# ADuCM363 register map
Vendor: Analog Devices Inc.; Series: ADuCM36x; File version: 0.1
CPU: CM3 r2p1, little endian, no MPU, no FPU, 3 interrupt priority bits
Registers are 16-bit, read-write, no defined reset value unless marked. A register's access mark holds for its fields unless they carry their own. Offsets are from the block's base; [hi:lo] are bit positions; {n}, {i} and the like mark numbered series.

## ADI_GPIO1 — General Purpose Input Output
Base 0x40006030
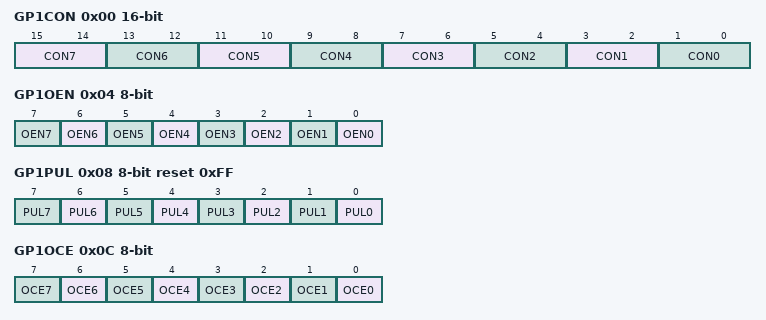
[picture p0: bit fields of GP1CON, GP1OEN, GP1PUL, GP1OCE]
0x00 GP1CON — GPIO Port 1 configuration
  [15:14] CON7 — Configuration bits for P1.7
    0=GPIOIRQ7; 1=PWM5; 2=SPI0CS
  [13:12] CON6 — Configuration bits for P1.6
    0=GPIOIRQ6; 1=PWM4; 2=SPI0MOSI
  [11:10] CON5 — Configuration bits for P1.5
    0=GPIOIRQ5; 1=PWM3; 2=SPI0SCLK
  [9:8] CON4 — Configuration bits for P1.4
    0=GPIO; 1=PWM2; 2=SPI0MISO
  [7:6] CON3 — Configuration bits for P1.3
    0=GPIO; 1=PWM1
  [5:4] CON2 — Configuration bits for P1.2
    0=GPIO; 1=PWM0
  [3:2] CON1 — Configuration bits for P1.1
    0=GPIOIRQ4; 1=PWMTRIP
  [1:0] CON0 — Configuration bits for P1.0
    0=GPIOIRQ3; 1=PWMSYNC; 2=EXTCLKIN
0x04 GP1OEN 8-bit — GPIO Port 1 output enable
  [all] fields
    0=IN; 1=OUT
  [n] OEN{n} (n=0..7) — Direction for port pin
0x08 GP1PUL 8-bit reset 0xFF (reset mask 0x0) — GPIO Port 1 output pull up enable.
  [all] fields
    0=DIS; 1=EN
  [n] PUL{n} (n=0..7) — Pull Up Enable for port pin
0x0C GP1OCE 8-bit — GPIO Port 1 tri state
  [all] fields
    0=DIS; 1=EN
  [n] OCE{n} (n=0..7) — open circuit Enable for port pin
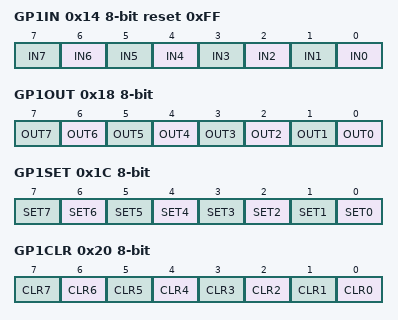
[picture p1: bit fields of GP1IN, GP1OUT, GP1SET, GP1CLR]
0x14 GP1IN 8-bit ro reset 0xFF (reset mask 0x0) — GPIO Port 1 data input.
  [all] fields
    0=LOW; 1=HIGH
  [n] IN{n} (n=0..7) — Input for port pin
0x18 GP1OUT 8-bit — GPIO Port 1 data out.
  [all] fields
    0=LOW; 1=HIGH
  [n] OUT{n} (n=0..7) — Output for port pin
0x1C GP1SET 8-bit wo — GPIO Port 1 data out set
  [all] fields
    1=SET
  [n] SET{n} (n=0..7) — Set Output High for port pin
0x20 GP1CLR 8-bit wo — GPIO Port 1 data out clear.
  [all] fields
    1=CLR
  [n] CLR{n} (n=0..7) — Set Output Low for port pin
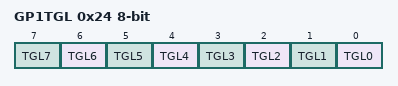
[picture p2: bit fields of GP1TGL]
0x24 GP1TGL 8-bit wo — GPIO Port 1 pin toggle.
  [all] fields
    1=TGL
  [n] TGL{n} (n=0..7) — Toggle Output for port pin

## ADI_GPIO2 — General Purpose Input Output
Base 0x40006060
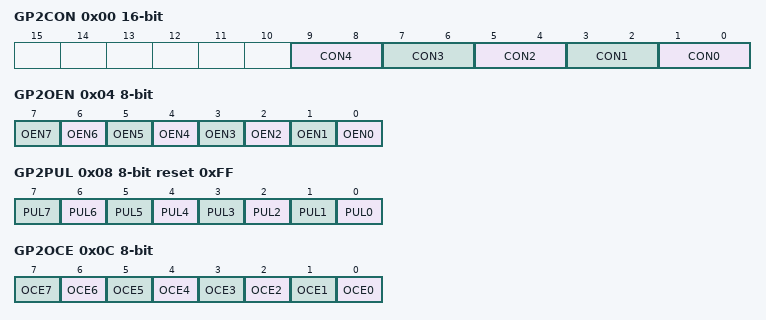
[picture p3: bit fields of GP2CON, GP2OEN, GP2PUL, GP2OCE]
0x00 GP2CON — GPIO Port 2 configuration
  [9:8] CON4 — Configuration bits for P2.4
    1=SWDATA
  [7:6] CON3 — Configuration bits for P2.3
    1=SWCLK
  [5:4] CON2 — Configuration bits for P2.2
    0=GPIO
  [3:2] CON1 — Configuration bits for P2.1
    0=GPIO; 1=I2CSDA
  [1:0] CON0 — Configuration bits for P2.0
    0=GPIO; 1=I2CSCL
0x04 GP2OEN 8-bit — GPIO Port 2 output enable
  [all] fields
    0=IN; 1=OUT
  [n] OEN{n} (n=0..7) — Direction for port pin
0x08 GP2PUL 8-bit reset 0xFF (reset mask 0x0) — GPIO Port 2 output pull up enable.
  [all] fields
    0=DIS; 1=EN
  [n] PUL{n} (n=0..7) — Pull Up Enable for port pin
0x0C GP2OCE 8-bit — GPIO Port 2 tri state
  [all] fields
    0=DIS; 1=EN
  [n] OCE{n} (n=0..7) — open circuit Enable for port pin
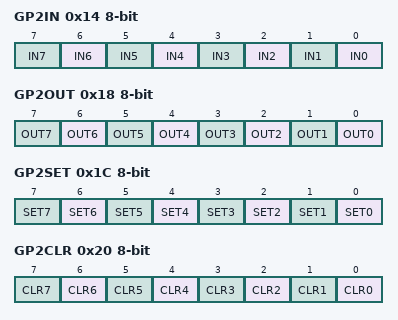
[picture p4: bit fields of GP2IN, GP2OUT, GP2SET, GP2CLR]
0x14 GP2IN 8-bit ro — GPIO Port 2 data input.
  [all] fields
    0=LOW; 1=HIGH
  [n] IN{n} (n=0..7) — Input for port pin
0x18 GP2OUT 8-bit — GPIO Port 2 data out.
  [all] fields
    0=LOW; 1=HIGH
  [n] OUT{n} (n=0..7) — Output for port pin
0x1C GP2SET 8-bit wo — GPIO Port 2 data out set
  [all] fields
    1=SET
  [n] SET{n} (n=0..7) — Set Output High for port pin
0x20 GP2CLR 8-bit wo — GPIO Port 2 data out clear.
  [all] fields
    1=CLR
  [n] CLR{n} (n=0..7) — Set Output Low for port pin
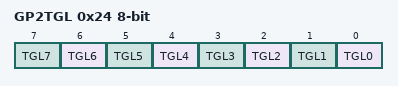
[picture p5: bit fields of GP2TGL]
0x24 GP2TGL 8-bit wo — GPIO Port 2 pin toggle.
  [all] fields
    1=TGL
  [n] TGL{n} (n=0..7) — Toggle Output for port pin

## ADI_ANA — Analog Control
Base 0x40008810
0x30 REFCTRL — Internal Reference Control register
  [0] REFPD — Power down reference
    0=DIS; 1=EN
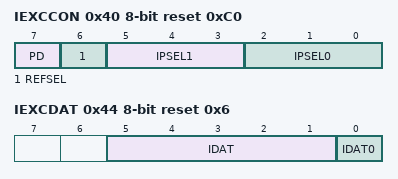
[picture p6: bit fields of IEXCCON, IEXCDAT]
0x40 IEXCCON 8-bit reset 0xC0 (reset mask 0x0) — Controls the on-chip Excitation Current Sources
  [7] PD — IEXC Power down- bits
    1=En; 0=off
  [6] REFSEL — IREF Source- bits
    0=Ext; 1=Int
  [5:3] IPSEL1 — Select IEXC1 pin AIN- bits
    0=Off; {v}=AIN{v} (v=4..7)
  [2:0] IPSEL0 — Select IEXC0 pin AIN- bits
    0=Off; {v}=AIN{v} (v=4..7)
0x44 IEXCDAT 8-bit reset 0x6 (reset mask 0x0) — Sets the output current setting for both Excitation Current sources
  [5:1] IDAT — Output Current- bits
    0=0uA; 4=50uA; 5=100uA; 6=150uA; 7=200uA; 20=250uA; 10=300uA; 11=400uA; 14=450uA; 21=500uA; 15=600uA; 22=750uA; 19=800uA; 31=1mA
  [0] IDAT0 — 10uA Enable
    0=DIS; 1=EN

## ADI_ADCSTEP — Analog to Digital Converter
Base 0x400300E0
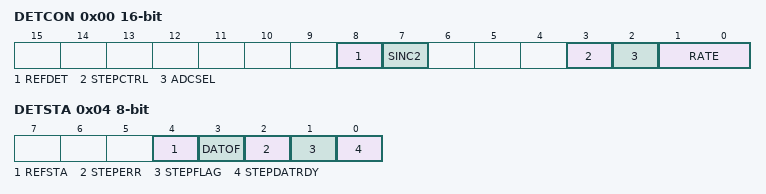
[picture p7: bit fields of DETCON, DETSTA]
0x00 DETCON — Control register for reference detection and the step detection filter
  [8] REFDET — Enable external reference detection circuit
    0=DIS; 1=EN
  [7] SINC2 — Enable Sinc2 filter
    0=DIS; 1=EN
  [3] STEPCTRL — Control the method to generate the step flag
    0=DIS; 1=EN
  [2] ADCSEL — Select ADC
    0=DIS; 1=EN
  [1:0] RATE range 0x00000000..0x00000003 — Control the sinc2 filter's time interval
0x04 DETSTA 8-bit ro — Status register for detection
  [all] fields
    0=DIS; 1=EN
  [4] REFSTA
  [3] DATOF — STEPDAT Overflow
  [2] STEPERR
  [1] STEPFLAG
  [0] STEPDATRDY
0x08 STEPTH — Threshold for step detection filter
  [8:0] VALUE range 0x00000000..0x000001FF
0x0C STEPDAT 32-bit ro — Offers coarse data from the output of the step detection filter
  [31:0] VALUE range 0x00000000..0xFFFFFFFF

## ADI_ADCDMA — Analog to Digital Converter
Base 0x400300F0
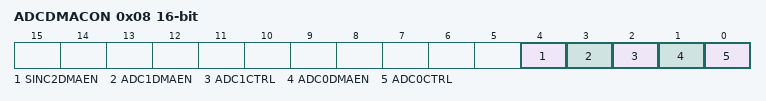
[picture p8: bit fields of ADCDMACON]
0x08 ADCDMACON — ADC DMA mode Configuration register
  [all] fields
    0=DIS; 1=EN
  [4] SINC2DMAEN
  [3] ADC1DMAEN
  [2] ADC1CTRL
  [1] ADC0DMAEN
  [0] ADC0CTRL

## ADI_DAC — Digital To Analog Converter
Base 0x40020000
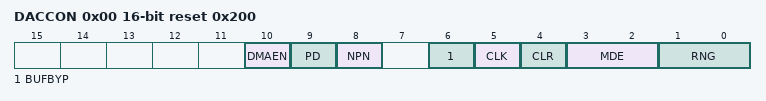
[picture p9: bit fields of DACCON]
0x00 DACCON reset 0x200 (reset mask 0x0) — Control Register
  [10] DMAEN — bits
    0=Off; 1=On
  [9] PD
    0=DIS; 1=EN
  [8] NPN
    0=DIS; 1=EN
  [6] BUFBYP
    0=DIS; 1=EN
  [5] CLK — bits
    0=HCLK; 1=Timer1
  [4] CLR — bits
    1=Off; 0=On
  [3:2] MDE — Mode bits
    0=12bit; 3=16BitSlow; 2=16BitFast
  [1:0] RNG — DAC Range bits
    0=IntVref; 3=AVdd
0x04 DACDAT 32-bit — Data Register
  [31:12] VALUE range 0x00000000..0x000FFFFF — Data
